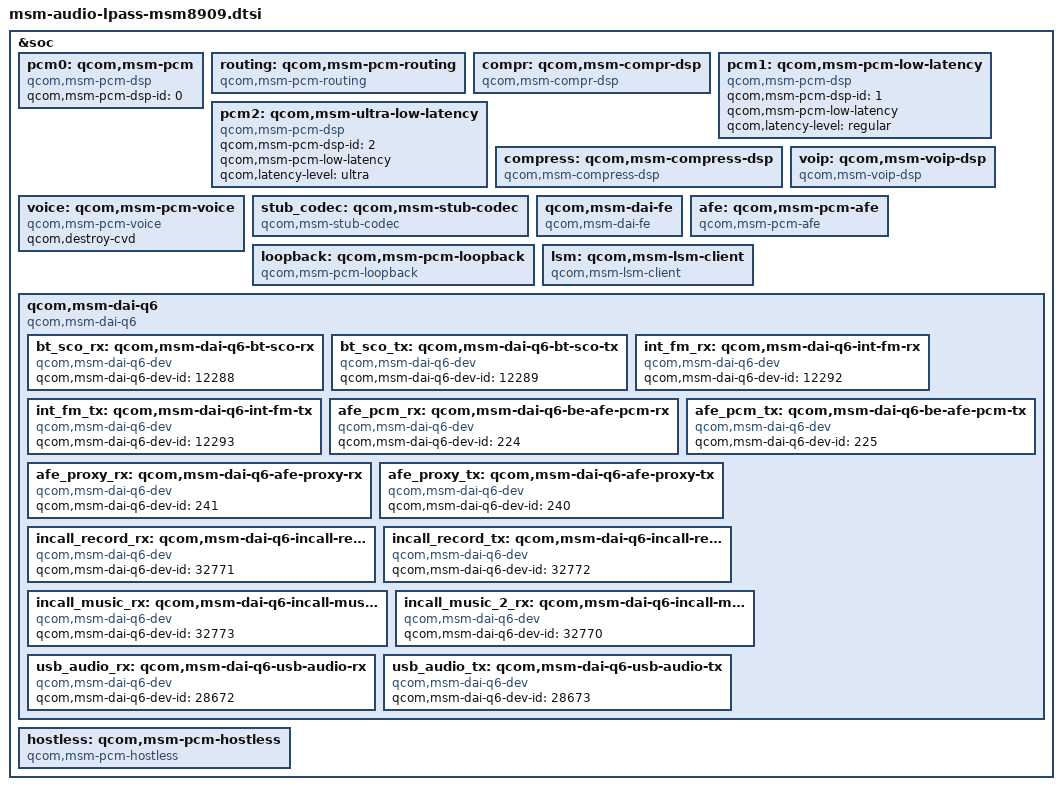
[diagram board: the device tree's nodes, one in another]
/*
 * Copyright (c) 2016-2018, The Linux Foundation. All rights reserved.
 *
 * This program is free software; you can redistribute it and/or modify
 * it under the terms of the GNU General Public License version 2 and
 * only version 2 as published by the Free Software Foundation.
 *
 * This program is distributed in the hope that it will be useful,
 * but WITHOUT ANY WARRANTY; without even the implied warranty of
 * MERCHANTABILITY or FITNESS FOR A PARTICULAR PURPOSE.  See the
 * GNU General Public License for more details.
 */

&soc {
	pcm0: qcom,msm-pcm {
		compatible = "qcom,msm-pcm-dsp";
		qcom,msm-pcm-dsp-id = <0>;
	};

	routing: qcom,msm-pcm-routing {
		compatible = "qcom,msm-pcm-routing";
	};

	compr: qcom,msm-compr-dsp {
		compatible = "qcom,msm-compr-dsp";
	};

	pcm1: qcom,msm-pcm-low-latency {
		compatible = "qcom,msm-pcm-dsp";
		qcom,msm-pcm-dsp-id = <1>;
		qcom,msm-pcm-low-latency;
		qcom,latency-level = "regular";
	};

	pcm2: qcom,msm-ultra-low-latency {
		compatible = "qcom,msm-pcm-dsp";
		qcom,msm-pcm-dsp-id = <2>;
		qcom,msm-pcm-low-latency;
		qcom,latency-level = "ultra";
	};

	compress: qcom,msm-compress-dsp {
		compatible = "qcom,msm-compress-dsp";
	};

	voip: qcom,msm-voip-dsp {
		compatible = "qcom,msm-voip-dsp";
	};

	voice: qcom,msm-pcm-voice {
		compatible = "qcom,msm-pcm-voice";
		qcom,destroy-cvd;
	};

	stub_codec: qcom,msm-stub-codec {
		compatible = "qcom,msm-stub-codec";
	};

	qcom,msm-dai-fe {
		compatible = "qcom,msm-dai-fe";
	};

	afe: qcom,msm-pcm-afe {
		compatible = "qcom,msm-pcm-afe";
	};

	loopback: qcom,msm-pcm-loopback {
		compatible = "qcom,msm-pcm-loopback";
	};

	lsm: qcom,msm-lsm-client {
		compatible = "qcom,msm-lsm-client";
	};

	qcom,msm-dai-q6 {
		compatible = "qcom,msm-dai-q6";
		bt_sco_rx: qcom,msm-dai-q6-bt-sco-rx {
			compatible = "qcom,msm-dai-q6-dev";
			qcom,msm-dai-q6-dev-id = <12288>;
		};

		bt_sco_tx: qcom,msm-dai-q6-bt-sco-tx {
			compatible = "qcom,msm-dai-q6-dev";
			qcom,msm-dai-q6-dev-id = <12289>;
		};

		int_fm_rx: qcom,msm-dai-q6-int-fm-rx {
			compatible = "qcom,msm-dai-q6-dev";
			qcom,msm-dai-q6-dev-id = <12292>;
		};

		int_fm_tx: qcom,msm-dai-q6-int-fm-tx {
			compatible = "qcom,msm-dai-q6-dev";
			qcom,msm-dai-q6-dev-id = <12293>;
		};

		afe_pcm_rx: qcom,msm-dai-q6-be-afe-pcm-rx {
			compatible = "qcom,msm-dai-q6-dev";
			qcom,msm-dai-q6-dev-id = <224>;
		};

		afe_pcm_tx: qcom,msm-dai-q6-be-afe-pcm-tx {
			compatible = "qcom,msm-dai-q6-dev";
			qcom,msm-dai-q6-dev-id = <225>;
		};

		afe_proxy_rx: qcom,msm-dai-q6-afe-proxy-rx {
			compatible = "qcom,msm-dai-q6-dev";
			qcom,msm-dai-q6-dev-id = <241>;
		};

		afe_proxy_tx: qcom,msm-dai-q6-afe-proxy-tx {
			compatible = "qcom,msm-dai-q6-dev";
			qcom,msm-dai-q6-dev-id = <240>;
		};

		incall_record_rx: qcom,msm-dai-q6-incall-record-rx {
			compatible = "qcom,msm-dai-q6-dev";
			qcom,msm-dai-q6-dev-id = <32771>;
		};

		incall_record_tx: qcom,msm-dai-q6-incall-record-tx {
			compatible = "qcom,msm-dai-q6-dev";
			qcom,msm-dai-q6-dev-id = <32772>;
		};

		incall_music_rx: qcom,msm-dai-q6-incall-music-rx {
			compatible = "qcom,msm-dai-q6-dev";
			qcom,msm-dai-q6-dev-id = <32773>;
		};

		incall_music_2_rx: qcom,msm-dai-q6-incall-music-2-rx {
			compatible = "qcom,msm-dai-q6-dev";
			qcom,msm-dai-q6-dev-id = <32770>;
		};

		usb_audio_rx: qcom,msm-dai-q6-usb-audio-rx {
			compatible = "qcom,msm-dai-q6-dev";
			qcom,msm-dai-q6-dev-id = <28672>;
		};

		usb_audio_tx: qcom,msm-dai-q6-usb-audio-tx {
			compatible = "qcom,msm-dai-q6-dev";
			qcom,msm-dai-q6-dev-id = <28673>;
		};
	};

	hostless: qcom,msm-pcm-hostless {
		compatible = "qcom,msm-pcm-hostless";
	};

};
